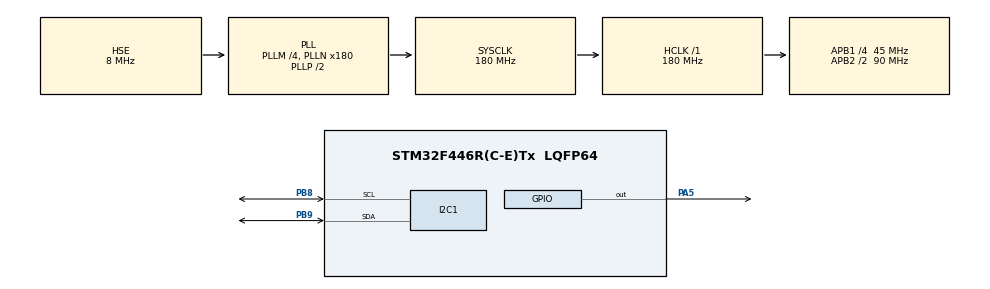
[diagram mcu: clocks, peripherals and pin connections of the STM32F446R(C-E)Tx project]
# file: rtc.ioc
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Mcu.Family=STM32F4
Mcu.Name=STM32F446R(C-E)Tx
Mcu.Package=LQFP64
NVIC.PriorityGroup=NVIC_PRIORITYGROUP_4
NVIC.RTC_Alarm_IRQn=true\:0\:0\:false\:false\:true\:true
PA5.Signal=GPIO_Output
PB8.Mode=I2C
PB8.Signal=I2C1_SCL
PB9.Mode=I2C
PB9.Signal=I2C1_SDA
PC14-OSC32_IN.Mode=LSE-External-Oscillator
PC14-OSC32_IN.Signal=RCC_OSC32_IN
PC15-OSC32_OUT.Mode=LSE-External-Oscillator
PC15-OSC32_OUT.Signal=RCC_OSC32_OUT
PH0-OSC_IN.Mode=HSE-External-Oscillator
PH0-OSC_IN.Signal=RCC_OSC_IN
PH1-OSC_OUT.Mode=HSE-External-Oscillator
PH1-OSC_OUT.Signal=RCC_OSC_OUT
ProjectManager.HeapSize=0x200
ProjectManager.StackSize=0x400
ProjectManager.TargetToolchain=SW4STM32
RCC.AHBFreq_Value=180000000
RCC.APB1CLKDivider=RCC_HCLK_DIV4
RCC.APB1Freq_Value=45000000
RCC.APB1TimFreq_Value=90000000
RCC.APB2CLKDivider=RCC_HCLK_DIV2
RCC.APB2Freq_Value=90000000
RCC.APB2TimFreq_Value=180000000
RCC.CortexFreq_Value=180000000
RCC.HCLKFreq_Value=180000000
RCC.HSE_VALUE=8000000
RCC.PLLM=4
RCC.PLLN=180
RCC.PLLSourceVirtual=RCC_PLLSOURCE_HSE
RCC.RCC_RTC_Clock_SourceVirtual=RCC_RTCCLKSOURCE_LSE
RCC.SYSCLKFreq_VALUE=180000000
RCC.SYSCLKSource=RCC_SYSCLKSOURCE_PLLCLK
RCC.USBFreq_Value=180000000
RCC.VCOOutputFreq_Value=360000000
RTC.Alarm=RTC_ALARM_A
RTC.AlarmDateWeekDay=12
RTC.Date=12
RTC.Hours=10
RTC.Hours_A=10
RTC.Minutes=20
RTC.Minutes_A=21
RTC.Month=RTC_MONTH_AUGUST
RTC.Seconds=30
RTC.WeekDay=RTC_WEEKDAY_TUESDAY
VP_RTC_VS_RTC_Activate.Mode=RTC_Enabled
VP_RTC_VS_RTC_Alarm_A_Intern.Mode=Alarm A
VP_RTC_VS_RTC_Calendar.Mode=RTC_Calendar
board=custom

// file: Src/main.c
/**
  ******************************************************************************
  * @file           : main.c
  * @brief          : Main program body
  ******************************************************************************
  ** This notice applies to any and all portions of this file
  * that are not between comment pairs USER CODE BEGIN and
  * USER CODE END. Other portions of this file, whether
  * inserted by the user or by software development tools
  * are owned by their respective copyright owners.
  *
  * COPYRIGHT(c) 2018 STMicroelectronics
  *
  * Redistribution and use in source and binary forms, with or without modification,
  * are permitted provided that the following conditions are met:
  *   1. Redistributions of source code must retain the above copyright notice,
  *      this list of conditions and the following disclaimer.
  *   2. Redistributions in binary form must reproduce the above copyright notice,
  *      this list of conditions and the following disclaimer in the documentation
  *      and/or other materials provided with the distribution.
  *   3. Neither the name of STMicroelectronics nor the names of its contributors
  *      may be used to endorse or promote products derived from this software
  *      without specific prior written permission.
  *
  * THIS SOFTWARE IS PROVIDED BY THE COPYRIGHT HOLDERS AND CONTRIBUTORS "AS IS"
  * AND ANY EXPRESS OR IMPLIED WARRANTIES, INCLUDING, BUT NOT LIMITED TO, THE
  * IMPLIED WARRANTIES OF MERCHANTABILITY AND FITNESS FOR A PARTICULAR PURPOSE ARE
  * DISCLAIMED. IN NO EVENT SHALL THE COPYRIGHT HOLDER OR CONTRIBUTORS BE LIABLE
  * FOR ANY DIRECT, INDIRECT, INCIDENTAL, SPECIAL, EXEMPLARY, OR CONSEQUENTIAL
  * DAMAGES (INCLUDING, BUT NOT LIMITED TO, PROCUREMENT OF SUBSTITUTE GOODS OR
  * SERVICES; LOSS OF USE, DATA, OR PROFITS; OR BUSINESS INTERRUPTION) HOWEVER
  * CAUSED AND ON ANY THEORY OF LIABILITY, WHETHER IN CONTRACT, STRICT LIABILITY,
  * OR TORT (INCLUDING NEGLIGENCE OR OTHERWISE) ARISING IN ANY WAY OUT OF THE USE
  * OF THIS SOFTWARE, EVEN IF ADVISED OF THE POSSIBILITY OF SUCH DAMAGE.
  *
  ******************************************************************************
  */
#include "main.h"
#include "stm32f4xx_hal.h"

/* USER CODE BEGIN Includes */
#include "i2c-lcd.h"
/* USER CODE END Includes */

I2C_HandleTypeDef hi2c1;

RTC_HandleTypeDef hrtc;

/* USER CODE BEGIN PV */
/* Private variables ---------------------------------------------------------*/

char time[10];
char date[10];

uint8_t alarm =0;

/* USER CODE END PV */

void SystemClock_Config(void);
static void MX_GPIO_Init(void);
static void MX_I2C1_Init(void);
static void MX_RTC_Init(void);

/* USER CODE BEGIN PFP */
/* Private function prototypes -----------------------------------------------*/

/* USER CODE END PFP */

/* USER CODE BEGIN 0 */
void set_time (void)
{
	  RTC_TimeTypeDef sTime;
	  RTC_DateTypeDef sDate;
    /**Initialize RTC and set the Time and Date
    */
  sTime.Hours = 0x10;
  sTime.Minutes = 0x20;
  sTime.Seconds = 0x30;
  sTime.DayLightSaving = RTC_DAYLIGHTSAVING_NONE;
  sTime.StoreOperation = RTC_STOREOPERATION_RESET;
  if (HAL_RTC_SetTime(&hrtc, &sTime, RTC_FORMAT_BCD) != HAL_OK)
  {
    _Error_Handler(__FILE__, __LINE__);
  }
  /* USER CODE BEGIN RTC_Init 3 */

  /* USER CODE END RTC_Init 3 */

  sDate.WeekDay = RTC_WEEKDAY_TUESDAY;
  sDate.Month = RTC_MONTH_AUGUST;
  sDate.Date = 0x12;
  sDate.Year = 0x0;

  if (HAL_RTC_SetDate(&hrtc, &sDate, RTC_FORMAT_BCD) != HAL_OK)
  {
    _Error_Handler(__FILE__, __LINE__);
  }
  /* USER CODE BEGIN RTC_Init 4 */

  HAL_RTCEx_BKUPWrite(&hrtc, RTC_BKP_DR1, 0x32F2);  // backup register

  /* USER CODE END RTC_Init 4 */
}

void set_alarm (void)
{
	  RTC_AlarmTypeDef sAlarm;

    /**Enable the Alarm A
    */
  sAlarm.AlarmTime.Hours = 0x10;
  sAlarm.AlarmTime.Minutes = 0x21;
  sAlarm.AlarmTime.Seconds = 0x0;
  sAlarm.AlarmTime.SubSeconds = 0x0;
  sAlarm.AlarmTime.DayLightSaving = RTC_DAYLIGHTSAVING_NONE;
  sAlarm.AlarmTime.StoreOperation = RTC_STOREOPERATION_RESET;
  sAlarm.AlarmMask = RTC_ALARMMASK_NONE;
  sAlarm.AlarmSubSecondMask = RTC_ALARMSUBSECONDMASK_ALL;
  sAlarm.AlarmDateWeekDaySel = RTC_ALARMDATEWEEKDAYSEL_DATE;
  sAlarm.AlarmDateWeekDay = 0x12;
  sAlarm.Alarm = RTC_ALARM_A;
  if (HAL_RTC_SetAlarm_IT(&hrtc, &sAlarm, RTC_FORMAT_BCD) != HAL_OK)
  {
    _Error_Handler(__FILE__, __LINE__);
  }
  /* USER CODE BEGIN RTC_Init 5 */

  /* USER CODE END RTC_Init 5 */
}

void get_time(void)
{
  RTC_DateTypeDef gDate;
  RTC_TimeTypeDef gTime;

  /* Get the RTC current Time */
  HAL_RTC_GetTime(&hrtc, &gTime, RTC_FORMAT_BIN);
  /* Get the RTC current Date */
  HAL_RTC_GetDate(&hrtc, &gDate, RTC_FORMAT_BIN);

  /* Display time Format: hh:mm:ss */
  sprintf((char*)time,"%02d:%02d:%02d",gTime.Hours, gTime.Minutes, gTime.Seconds);

  /* Display date Format: mm-dd-yy */
  sprintf((char*)date,"%02d-%02d-%2d",gDate.Date, gDate.Month, 2000 + gDate.Year);  // I like the date first
}

//Let's display the time and date on lcd

void display_time (void)
{
	lcd_send_cmd (0x80);
	lcd_send_string (time);
	lcd_send_cmd (0xc0);
	lcd_send_string (date);
}

void HAL_RTC_AlarmAEventCallback(RTC_HandleTypeDef *hrtc)
{
	alarm = 1;
}

void to_do_on_alarm (void)
{
	HAL_GPIO_WritePin (GPIOA, GPIO_PIN_5, 1);  // set led ON
	lcd_send_cmd (0x80);
	lcd_send_string ("SUBSCRIBE TO");
	lcd_send_cmd (0xc0);
	lcd_send_string ("this CHANNEL");
	HAL_Delay (3000);
	lcd_send_cmd (0x80);
	for (int i=0;i<60;i++)
	{
		lcd_send_data (' ');  // clear lcd
	}
}
/* USER CODE END 0 */

int main(void)
{

  /* MCU Configuration----------------------------------------------------------*/

  /* Reset of all peripherals, Initializes the Flash interface and the Systick. */
  HAL_Init();

  /* Configure the system clock */
  SystemClock_Config();

  /* Initialize all configured peripherals */
  MX_GPIO_Init();
  MX_I2C1_Init();
  MX_RTC_Init();
  /* USER CODE BEGIN 2 */

  lcd_init ();

  if(HAL_RTCEx_BKUPRead(&hrtc, RTC_BKP_DR1) != 0x32F2)
      {
      //   Set the time
        set_time();
      }

  set_alarm ();
  /* USER CODE END 2 */

  /* Infinite loop */
  while (1)
  {

  /* USER CODE BEGIN 3 */

	  get_time();
	  display_time();
	  HAL_Delay(500);

	  if (alarm)
	  {
		  to_do_on_alarm();
		  alarm =0;
	  }

  }
  /* USER CODE END 3 */

}

void SystemClock_Config(void)
{

  RCC_OscInitTypeDef RCC_OscInitStruct;
  RCC_ClkInitTypeDef RCC_ClkInitStruct;
  RCC_PeriphCLKInitTypeDef PeriphClkInitStruct;

    /**Configure the main internal regulator output voltage
    */
  __HAL_RCC_PWR_CLK_ENABLE();

  __HAL_PWR_VOLTAGESCALING_CONFIG(PWR_REGULATOR_VOLTAGE_SCALE1);

    /**Initializes the CPU, AHB and APB busses clocks
    */
  RCC_OscInitStruct.OscillatorType = RCC_OSCILLATORTYPE_HSE|RCC_OSCILLATORTYPE_LSE;
  RCC_OscInitStruct.HSEState = RCC_HSE_ON;
  RCC_OscInitStruct.LSEState = RCC_LSE_ON;
  RCC_OscInitStruct.PLL.PLLState = RCC_PLL_ON;
  RCC_OscInitStruct.PLL.PLLSource = RCC_PLLSOURCE_HSE;
  RCC_OscInitStruct.PLL.PLLM = 4;
  RCC_OscInitStruct.PLL.PLLN = 180;
  RCC_OscInitStruct.PLL.PLLP = RCC_PLLP_DIV2;
  RCC_OscInitStruct.PLL.PLLQ = 2;
  RCC_OscInitStruct.PLL.PLLR = 2;
  if (HAL_RCC_OscConfig(&RCC_OscInitStruct) != HAL_OK)
  {
    _Error_Handler(__FILE__, __LINE__);
  }

    /**Activate the Over-Drive mode
    */
  if (HAL_PWREx_EnableOverDrive() != HAL_OK)
  {
    _Error_Handler(__FILE__, __LINE__);
  }

    /**Initializes the CPU, AHB and APB busses clocks
    */
  RCC_ClkInitStruct.ClockType = RCC_CLOCKTYPE_HCLK|RCC_CLOCKTYPE_SYSCLK
                              |RCC_CLOCKTYPE_PCLK1|RCC_CLOCKTYPE_PCLK2;
  RCC_ClkInitStruct.SYSCLKSource = RCC_SYSCLKSOURCE_PLLCLK;
  RCC_ClkInitStruct.AHBCLKDivider = RCC_SYSCLK_DIV1;
  RCC_ClkInitStruct.APB1CLKDivider = RCC_HCLK_DIV4;
  RCC_ClkInitStruct.APB2CLKDivider = RCC_HCLK_DIV2;

  if (HAL_RCC_ClockConfig(&RCC_ClkInitStruct, FLASH_LATENCY_5) != HAL_OK)
  {
    _Error_Handler(__FILE__, __LINE__);
  }

  PeriphClkInitStruct.PeriphClockSelection = RCC_PERIPHCLK_RTC;
  PeriphClkInitStruct.RTCClockSelection = RCC_RTCCLKSOURCE_LSE;
  if (HAL_RCCEx_PeriphCLKConfig(&PeriphClkInitStruct) != HAL_OK)
  {
    _Error_Handler(__FILE__, __LINE__);
  }

    /**Configure the Systick interrupt time
    */
  HAL_SYSTICK_Config(HAL_RCC_GetHCLKFreq()/1000);

    /**Configure the Systick
    */
  HAL_SYSTICK_CLKSourceConfig(SYSTICK_CLKSOURCE_HCLK);

  /* SysTick_IRQn interrupt configuration */
  HAL_NVIC_SetPriority(SysTick_IRQn, 0, 0);
}

/* I2C1 init function */
static void MX_I2C1_Init(void)
{

  hi2c1.Instance = I2C1;
  hi2c1.Init.ClockSpeed = 100000;
  hi2c1.Init.DutyCycle = I2C_DUTYCYCLE_2;
  hi2c1.Init.OwnAddress1 = 0;
  hi2c1.Init.AddressingMode = I2C_ADDRESSINGMODE_7BIT;
  hi2c1.Init.DualAddressMode = I2C_DUALADDRESS_DISABLE;
  hi2c1.Init.OwnAddress2 = 0;
  hi2c1.Init.GeneralCallMode = I2C_GENERALCALL_DISABLE;
  hi2c1.Init.NoStretchMode = I2C_NOSTRETCH_DISABLE;
  if (HAL_I2C_Init(&hi2c1) != HAL_OK)
  {
    _Error_Handler(__FILE__, __LINE__);
  }

}

/* RTC init function */
static void MX_RTC_Init(void)
{

    /**Initialize RTC Only
    */
  hrtc.Instance = RTC;
  hrtc.Init.HourFormat = RTC_HOURFORMAT_24;
  hrtc.Init.AsynchPrediv = 127;
  hrtc.Init.SynchPrediv = 255;
  hrtc.Init.OutPut = RTC_OUTPUT_DISABLE;
  hrtc.Init.OutPutPolarity = RTC_OUTPUT_POLARITY_HIGH;
  hrtc.Init.OutPutType = RTC_OUTPUT_TYPE_OPENDRAIN;
  if (HAL_RTC_Init(&hrtc) != HAL_OK)
  {
    _Error_Handler(__FILE__, __LINE__);
  }

}

/** Configure pins as
        * Analog
        * Input
        * Output
        * EVENT_OUT
        * EXTI
*/
static void MX_GPIO_Init(void)
{

  GPIO_InitTypeDef GPIO_InitStruct;

  /* GPIO Ports Clock Enable */
  __HAL_RCC_GPIOC_CLK_ENABLE();
  __HAL_RCC_GPIOH_CLK_ENABLE();
  __HAL_RCC_GPIOA_CLK_ENABLE();
  __HAL_RCC_GPIOB_CLK_ENABLE();

  /*Configure GPIO pin Output Level */
  HAL_GPIO_WritePin(GPIOA, GPIO_PIN_5, GPIO_PIN_RESET);

  /*Configure GPIO pin : PA5 */
  GPIO_InitStruct.Pin = GPIO_PIN_5;
  GPIO_InitStruct.Mode = GPIO_MODE_OUTPUT_PP;
  GPIO_InitStruct.Pull = GPIO_NOPULL;
  GPIO_InitStruct.Speed = GPIO_SPEED_FREQ_LOW;
  HAL_GPIO_Init(GPIOA, &GPIO_InitStruct);

}

void _Error_Handler(char *file, int line)
{
  while(1)
  {
  }
}

/************************ (C) COPYRIGHT STMicroelectronics *****END OF FILE****/
